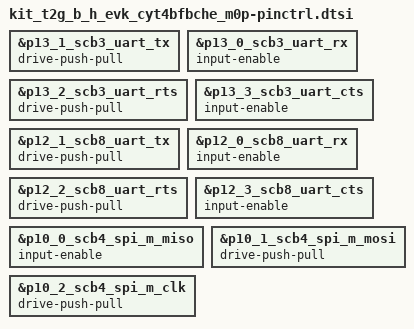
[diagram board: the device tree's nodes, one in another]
/*
 * SPDX-FileCopyrightText: <text>Copyright (c) 2026 Infineon Technologies AG,
 * or an affiliate of Infineon Technologies AG. All rights reserved.</text>
 *
 * SPDX-License-Identifier: Apache-2.0
 */

#include <arm/infineon/cat1c/traveo/cyt4bf/cyt4bfb-pinctrl.dtsi>
/* Configure pin control bias mode for uart pins */
&p13_1_scb3_uart_tx {
	drive-push-pull;
};

&p13_0_scb3_uart_rx {
	input-enable;
};

&p13_2_scb3_uart_rts {
	drive-push-pull;
};

&p13_3_scb3_uart_cts {
	input-enable;
};

&p12_1_scb8_uart_tx {
	drive-push-pull;
};

&p12_0_scb8_uart_rx {
	input-enable;
};

&p12_2_scb8_uart_rts {
	drive-push-pull;
};

&p12_3_scb8_uart_cts {
	input-enable;
};

&p10_0_scb4_spi_m_miso {
	input-enable;
};

&p10_1_scb4_spi_m_mosi {
	drive-push-pull;
};

&p10_2_scb4_spi_m_clk {
	drive-push-pull;
};
